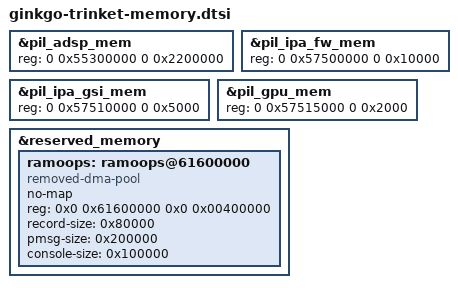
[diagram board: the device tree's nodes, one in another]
&pil_adsp_mem {
    reg = <0 0x55300000 0 0x2200000>;
};

&pil_ipa_fw_mem {
    reg = <0 0x57500000 0 0x10000>;
};

&pil_ipa_gsi_mem {
    reg = <0 0x57510000 0 0x5000>;
};

&pil_gpu_mem {
    reg = <0 0x57515000 0 0x2000>;
};

&reserved_memory {
	ramoops: ramoops@61600000 {
		compatible = "removed-dma-pool", "ramoops";
		no-map;
		reg = <0x0 0x61600000 0x0 0x00400000>;

		record-size = <0x80000>;
		pmsg-size = <0x200000>;
		console-size = <0x100000>;
	};
};
